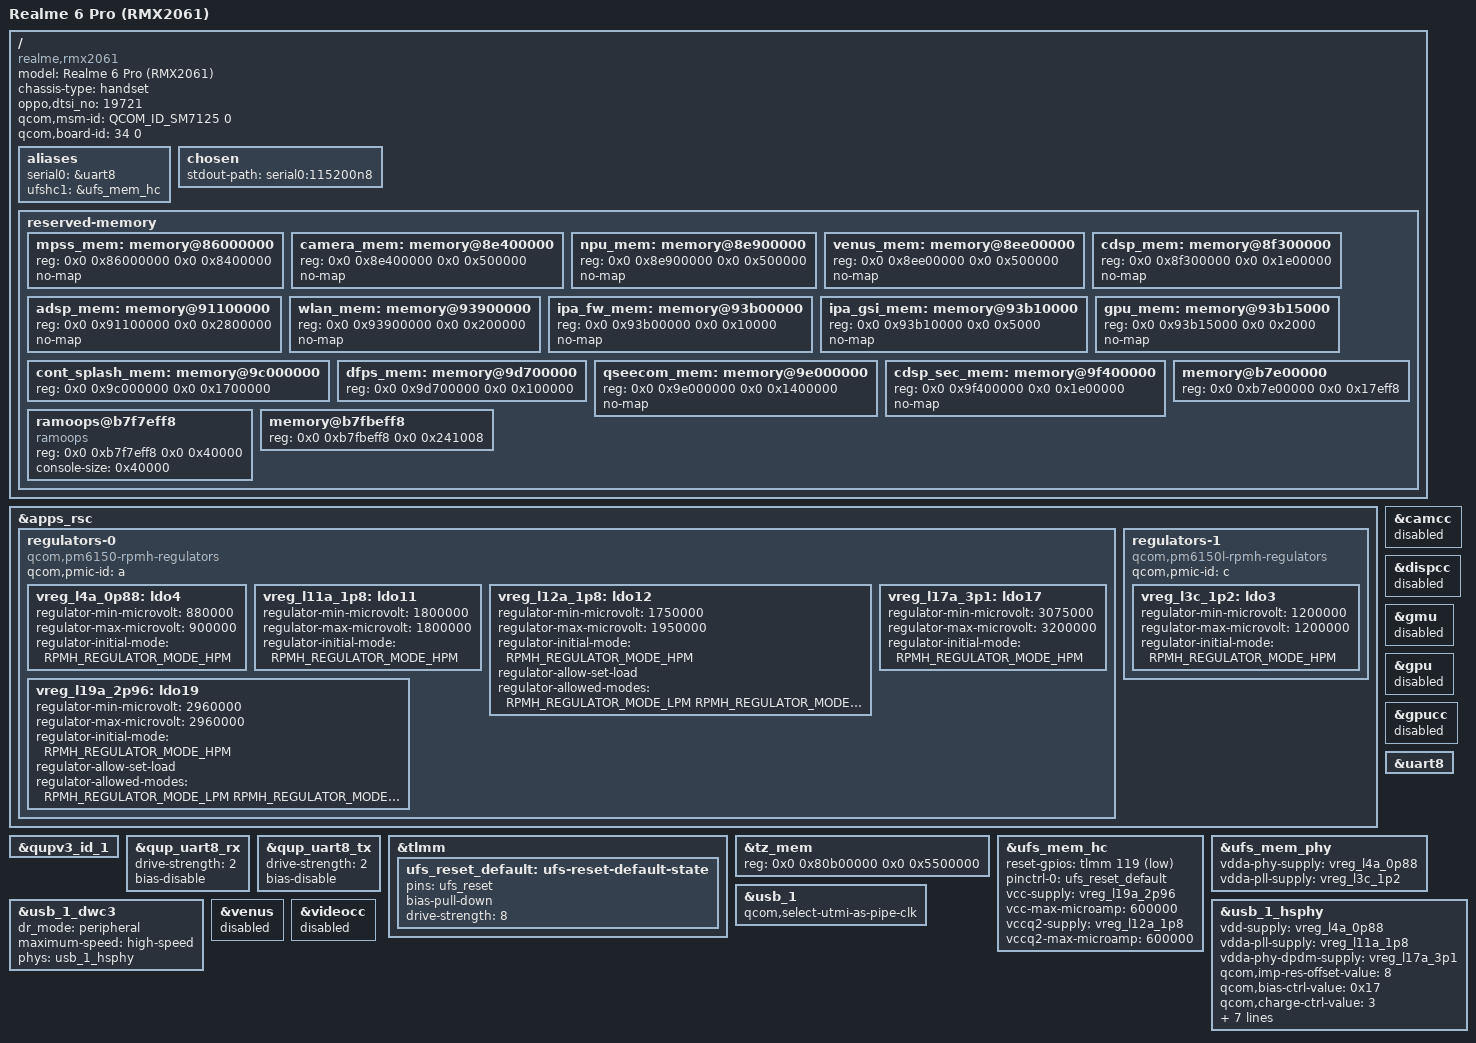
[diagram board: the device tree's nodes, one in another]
// SPDX-License-Identifier: GPL-2.0-only
/*
 * Copyright (c) 2019-2020, The Linux Foundation. All rights reserved.
 */

/dts-v1/;

#include <dt-bindings/arm/qcom,ids.h>
#include <dt-bindings/gpio/gpio.h>
#include <dt-bindings/phy/phy-qcom-qusb2.h>
#include <dt-bindings/regulator/qcom,rpmh-regulator.h>
#include "sm7125.dtsi"
#include "pm6150.dtsi"
#include "pm6150l.dtsi"

/delete-node/ &ipa_fw_mem;
/delete-node/ &rmtfs_mem;

/ {
	model = "Realme 6 Pro (RMX2061)";
	compatible = "realme,rmx2061", "qcom,sm7125";
	chassis-type = "handset";

	/* Retain the Atoll-AB selectors used by the shipping bootloader. */
	oppo,dtsi_no = <19721>;
	qcom,msm-id = <QCOM_ID_SM7125 0>;
	qcom,board-id = <34 0>;

	aliases {
		serial0 = &uart8;
		ufshc1 = &ufs_mem_hc;
	};

	chosen {
		stdout-path = "serial0:115200n8";
	};

	reserved-memory {
		mpss_mem: memory@86000000 {
			reg = <0x0 0x86000000 0x0 0x8400000>;
			no-map;
		};

		camera_mem: memory@8e400000 {
			reg = <0x0 0x8e400000 0x0 0x500000>;
			no-map;
		};

		npu_mem: memory@8e900000 {
			reg = <0x0 0x8e900000 0x0 0x500000>;
			no-map;
		};

		venus_mem: memory@8ee00000 {
			reg = <0x0 0x8ee00000 0x0 0x500000>;
			no-map;
		};

		cdsp_mem: memory@8f300000 {
			reg = <0x0 0x8f300000 0x0 0x1e00000>;
			no-map;
		};

		adsp_mem: memory@91100000 {
			reg = <0x0 0x91100000 0x0 0x2800000>;
			no-map;
		};

		wlan_mem: memory@93900000 {
			reg = <0x0 0x93900000 0x0 0x200000>;
			no-map;
		};

		ipa_fw_mem: memory@93b00000 {
			reg = <0x0 0x93b00000 0x0 0x10000>;
			no-map;
		};

		ipa_gsi_mem: memory@93b10000 {
			reg = <0x0 0x93b10000 0x0 0x5000>;
			no-map;
		};

		gpu_mem: memory@93b15000 {
			reg = <0x0 0x93b15000 0x0 0x2000>;
			no-map;
		};

		/* The vendor splash and display dump describe the same region. */
		cont_splash_mem: memory@9c000000 {
			reg = <0x0 0x9c000000 0x0 0x1700000>;
		};

		dfps_mem: memory@9d700000 {
			reg = <0x0 0x9d700000 0x0 0x100000>;
		};

		qseecom_mem: memory@9e000000 {
			reg = <0x0 0x9e000000 0x0 0x1400000>;
			no-map;
		};

		cdsp_sec_mem: memory@9f400000 {
			reg = <0x0 0x9f400000 0x0 0x1e00000>;
			no-map;
		};

		/* Keep the vendor dump slots reserved around its console buffer. */
		memory@b7e00000 {
			reg = <0x0 0xb7e00000 0x0 0x17eff8>;
		};

		/* Match the 4.14 console address for log recovery after rollback. */
		ramoops@b7f7eff8 {
			compatible = "ramoops";
			reg = <0x0 0xb7f7eff8 0x0 0x40000>;
			console-size = <0x40000>;
		};

		memory@b7fbeff8 {
			reg = <0x0 0xb7fbeff8 0x0 0x241008>;
		};
	};
};

&apps_rsc {
	regulators-0 {
		compatible = "qcom,pm6150-rpmh-regulators";
		qcom,pmic-id = "a";

		vreg_l4a_0p88: ldo4 {
			regulator-min-microvolt = <880000>;
			regulator-max-microvolt = <900000>;
			regulator-initial-mode = <RPMH_REGULATOR_MODE_HPM>;
		};

		vreg_l11a_1p8: ldo11 {
			regulator-min-microvolt = <1800000>;
			regulator-max-microvolt = <1800000>;
			regulator-initial-mode = <RPMH_REGULATOR_MODE_HPM>;
		};

		vreg_l12a_1p8: ldo12 {
			regulator-min-microvolt = <1750000>;
			regulator-max-microvolt = <1950000>;
			regulator-initial-mode = <RPMH_REGULATOR_MODE_HPM>;
			regulator-allow-set-load;
			regulator-allowed-modes = <RPMH_REGULATOR_MODE_LPM
						   RPMH_REGULATOR_MODE_HPM>;
		};

		vreg_l17a_3p1: ldo17 {
			regulator-min-microvolt = <3075000>;
			regulator-max-microvolt = <3200000>;
			regulator-initial-mode = <RPMH_REGULATOR_MODE_HPM>;
		};

		vreg_l19a_2p96: ldo19 {
			regulator-min-microvolt = <2960000>;
			regulator-max-microvolt = <2960000>;
			regulator-initial-mode = <RPMH_REGULATOR_MODE_HPM>;
			regulator-allow-set-load;
			regulator-allowed-modes = <RPMH_REGULATOR_MODE_LPM
						   RPMH_REGULATOR_MODE_HPM>;
		};
	};

	regulators-1 {
		compatible = "qcom,pm6150l-rpmh-regulators";
		qcom,pmic-id = "c";

		vreg_l3c_1p2: ldo3 {
			regulator-min-microvolt = <1200000>;
			regulator-max-microvolt = <1200000>;
			regulator-initial-mode = <RPMH_REGULATOR_MODE_HPM>;
		};
	};
};

&camcc {
	status = "disabled";
};

&dispcc {
	status = "disabled";
};

&gmu {
	status = "disabled";
};

&gpu {
	status = "disabled";
};

&gpucc {
	status = "disabled";
};

&qupv3_id_1 {
	status = "okay";
};

&qup_uart8_rx {
	drive-strength = <2>;
	bias-disable;
};

&qup_uart8_tx {
	drive-strength = <2>;
	bias-disable;
};

&tlmm {
	ufs_reset_default: ufs-reset-default-state {
		pins = "ufs_reset";
		bias-pull-down;
		drive-strength = <8>;
	};
};

&tz_mem {
	/* Split the vendor's overlapping removal/modem ranges at 0x86000000. */
	reg = <0x0 0x80b00000 0x0 0x5500000>;
};

&uart8 {
	status = "okay";
};

&ufs_mem_hc {
	reset-gpios = <&tlmm 119 GPIO_ACTIVE_LOW>;
	pinctrl-names = "default";
	pinctrl-0 = <&ufs_reset_default>;
	vcc-supply = <&vreg_l19a_2p96>;
	vcc-max-microamp = <600000>;
	vccq2-supply = <&vreg_l12a_1p8>;
	vccq2-max-microamp = <600000>;
	status = "okay";
};

&ufs_mem_phy {
	vdda-phy-supply = <&vreg_l4a_0p88>;
	vdda-pll-supply = <&vreg_l3c_1p2>;
	status = "okay";
};

&usb_1 {
	qcom,select-utmi-as-pipe-clk;
	status = "okay";
};

&usb_1_dwc3 {
	dr_mode = "peripheral";
	maximum-speed = "high-speed";
	phys = <&usb_1_hsphy>;
	phy-names = "usb2-phy";
	status = "okay";
};

&usb_1_hsphy {
	vdd-supply = <&vreg_l4a_0p88>;
	vdda-pll-supply = <&vreg_l11a_1p8>;
	vdda-phy-dpdm-supply = <&vreg_l17a_3p1>;
	qcom,imp-res-offset-value = <8>;
	qcom,bias-ctrl-value = <0x17>;
	qcom,charge-ctrl-value = <3>;
	/* The vendor driver treats a zero HSTX fuse as valid. */
	qcom,hstx-trim-value = <QUSB2_V2_HSTX_TRIM_24_0_MA>;
	qcom,preemphasis-level = <QUSB2_V2_PREEMPHASIS_15_PERCENT>;
	qcom,preemphasis-width = <QUSB2_V2_PREEMPHASIS_WIDTH_HALF_BIT>;
	qcom,hsdisc-trim-value = <0>;
	status = "okay";
};

&venus {
	status = "disabled";
};

&videocc {
	status = "disabled";
};
